AUTOSAR XML (schema 4-2-2)
package /ASW_COM_STD_Package
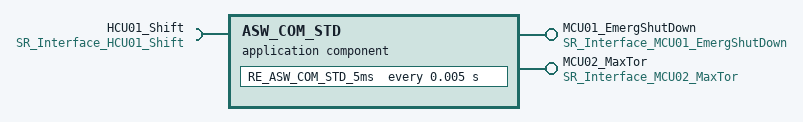
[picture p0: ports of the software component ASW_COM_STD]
  application sw component type ASW_COM_STD
    provide port MCU01_EmergShutDown: provided-interface=SR_Interface_MCU01_EmergShutDown
    provide port MCU02_MaxTor: provided-interface=SR_Interface_MCU02_MaxTor
    require port HCU01_Shift: non-queued-receiver-com-spec{data-element=DE_Shift, alive-timeout=0.3}, required-interface=SR_Interface_HCU01_Shift
    behavior IB_ASW_COM_STD
      timing event TE_ASW_COM_STD_5ms: start-on-event=RE_ASW_COM_STD_5ms, period=0.005
      runnable RE_ASW_COM_STD_5ms
        data-read-accesses:
          access READ_HCU01_Shift: accessed-variable=HCU01_Shift.DE_Shift
        data-write-accesses:
          access WRITE_MCU01_EmergShutDown: accessed-variable=MCU01_EmergShutDown.DE_EmergShutDown
          access WRITE_MCU02_MaxTor: accessed-variable=MCU02_MaxTor.DE_MaxTor
